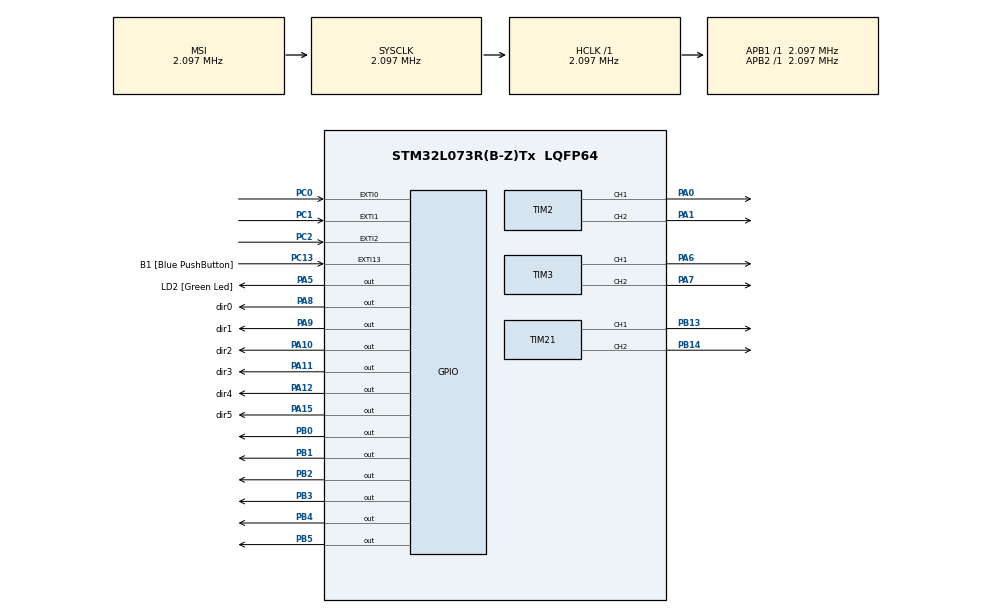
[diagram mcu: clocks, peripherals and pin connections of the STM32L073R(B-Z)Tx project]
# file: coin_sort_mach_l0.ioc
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FREERTOS.Tasks01=defaultTask,0,128,StartDefaultTask,Default
Mcu.Family=STM32L0
Mcu.Name=STM32L073R(B-Z)Tx
Mcu.Package=LQFP64
NVIC.EXTI0_1_IRQn=true\:3\:0\:false\:false\:true
NVIC.EXTI2_3_IRQn=true\:3\:0\:false\:false\:true
NVIC.EXTI4_15_IRQn=true\:3\:0\:false\:false\:true
NVIC.TIM21_IRQn=true\:3\:0\:false\:false\:true
NVIC.TIM2_IRQn=true\:3\:0\:false\:false\:true
NVIC.TIM3_IRQn=true\:3\:0\:false\:false\:true
PA0.Signal=S_TIM2_CH1
PA1.Signal=S_TIM2_CH2
PA10.GPIO_Label=dir2
PA10.Signal=GPIO_Output
PA11.GPIO_Label=dir3
PA11.Signal=GPIO_Output
PA12.GPIO_Label=dir4
PA12.Signal=GPIO_Output
PA13.GPIO_Label=TMS
PA13.Signal=SYS_SWDIO
PA14.GPIO_Label=TCK
PA14.Signal=SYS_SWCLK
PA15.GPIO_Label=dir5
PA15.Signal=GPIO_Output
PA2.GPIO_Label=USART_TX
PA2.Signal=USART2_TX
PA3.GPIO_Label=USART_RX
PA3.Signal=USART2_RX
PA5.GPIO_Label=LD2 [Green Led]
PA5.Signal=GPIO_Output
PA6.Signal=S_TIM3_CH1
PA7.Signal=S_TIM3_CH2
PA8.GPIO_Label=dir0
PA8.Signal=GPIO_Output
PA9.GPIO_Label=dir1
PA9.Signal=GPIO_Output
PB0.Signal=GPIO_Output
PB1.Signal=GPIO_Output
PB13.Signal=S_TIM21_CH1
PB14.Signal=S_TIM21_CH2
PB2.Signal=GPIO_Output
PB3.Signal=GPIO_Output
PB4.Signal=GPIO_Output
PB5.Signal=GPIO_Output
PC0.Signal=GPXTI0
PC1.Signal=GPXTI1
PC13.GPIO_Label=B1 [Blue PushButton]
PC13.Signal=GPXTI13
PC14-OSC32_IN.Signal=RCC_OSC32_IN
PC15-OSC32_OUT.Signal=RCC_OSC32_OUT
PC2.Signal=GPXTI2
PH0-OSC_IN.GPIO_Label=MCO
PH0-OSC_IN.Signal=RCC_OSC_IN
ProjectManager.HeapSize=0x200
ProjectManager.StackSize=0x400
ProjectManager.TargetToolchain=MDK-ARM V5
RCC.AHBFreq_Value=2097000
RCC.APB1Freq_Value=2097000
RCC.APB1TimFreq_Value=2097000
RCC.APB2Freq_Value=2097000
RCC.APB2TimFreq_Value=2097000
RCC.HSE_VALUE=8000000
RCC.HSI16_VALUE=16000000
RCC.HSI48_VALUE=48000000
RCC.HSI_VALUE=16000000
RCC.LSEState=RCC_LSE_ON
RCC.LSE_VALUE=32768
RCC.MSI_VALUE=2097000
RCC.SYSCLKFreq_VALUE=2097000
RCC.VCOOutputFreq_Value=48000000
SH.S_TIM21_CH1.0=TIM21_CH1,PWM Generation1 CH1
SH.S_TIM21_CH2.0=TIM21_CH2,PWM Generation2 CH2
SH.S_TIM2_CH1.0=TIM2_CH1,PWM Generation1 CH1
SH.S_TIM2_CH2.0=TIM2_CH2,PWM Generation2 CH2
SH.S_TIM3_CH1.0=TIM3_CH1,PWM Generation1 CH1
SH.S_TIM3_CH2.0=TIM3_CH2,PWM Generation2 CH2
TIM2.Channel-PWM\ Generation2\ CH2=TIM_CHANNEL_2
TIM21.Channel-PWM\ Generation2\ CH2=TIM_CHANNEL_2
TIM3.Channel-PWM\ Generation2\ CH2=TIM_CHANNEL_2
VP_FREERTOS_VS_ENABLE.Mode=Enabled
board=NUCLEO-L073RZ

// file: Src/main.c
/**
  ******************************************************************************
  * File Name          : main.c
  * Description        : Main program body
  ******************************************************************************
  *
  * COPYRIGHT(c) 2016 STMicroelectronics
  *
  * Redistribution and use in source and binary forms, with or without modification,
  * are permitted provided that the following conditions are met:
  *   1. Redistributions of source code must retain the above copyright notice,
  *      this list of conditions and the following disclaimer.
  *   2. Redistributions in binary form must reproduce the above copyright notice,
  *      this list of conditions and the following disclaimer in the documentation
  *      and/or other materials provided with the distribution.
  *   3. Neither the name of STMicroelectronics nor the names of its contributors
  *      may be used to endorse or promote products derived from this software
  *      without specific prior written permission.
  *
  * THIS SOFTWARE IS PROVIDED BY THE COPYRIGHT HOLDERS AND CONTRIBUTORS "AS IS"
  * AND ANY EXPRESS OR IMPLIED WARRANTIES, INCLUDING, BUT NOT LIMITED TO, THE
  * IMPLIED WARRANTIES OF MERCHANTABILITY AND FITNESS FOR A PARTICULAR PURPOSE ARE
  * DISCLAIMED. IN NO EVENT SHALL THE COPYRIGHT HOLDER OR CONTRIBUTORS BE LIABLE
  * FOR ANY DIRECT, INDIRECT, INCIDENTAL, SPECIAL, EXEMPLARY, OR CONSEQUENTIAL
  * DAMAGES (INCLUDING, BUT NOT LIMITED TO, PROCUREMENT OF SUBSTITUTE GOODS OR
  * SERVICES; LOSS OF USE, DATA, OR PROFITS; OR BUSINESS INTERRUPTION) HOWEVER
  * CAUSED AND ON ANY THEORY OF LIABILITY, WHETHER IN CONTRACT, STRICT LIABILITY,
  * OR TORT (INCLUDING NEGLIGENCE OR OTHERWISE) ARISING IN ANY WAY OUT OF THE USE
  * OF THIS SOFTWARE, EVEN IF ADVISED OF THE POSSIBILITY OF SUCH DAMAGE.
  *
  ******************************************************************************
  */
#include "stm32l0xx_hal.h"
#include "cmsis_os.h"
#include "tim.h"
#include "gpio.h"

/* USER CODE BEGIN PV */
/* Private variables ---------------------------------------------------------*/

/* USER CODE END PV */

void SystemClock_Config(void);
void MX_FREERTOS_Init(void);

/* USER CODE BEGIN PFP */
/* Private function prototypes -----------------------------------------------*/

/* USER CODE END PFP */

int main(void)
{

  /* MCU Configuration----------------------------------------------------------*/

  /* Reset of all peripherals, Initializes the Flash interface and the Systick. */
  HAL_Init();

  /* Configure the system clock */
  SystemClock_Config();

  /* Initialize all configured peripherals */
  MX_GPIO_Init();
  MX_TIM2_Init();
  MX_TIM3_Init();
  MX_TIM21_Init();

  /* USER CODE BEGIN 2 */
  HAL_GPIO_WritePin(GPIOA,dir1_Pin,GPIO_PIN_RESET);
  /* USER CODE END 2 */

  /* Call init function for freertos objects (in freertos.c) */
  MX_FREERTOS_Init();

  /* Start scheduler */
  osKernelStart();

  /* We should never get here as control is now taken by the scheduler */

  /* Infinite loop */
  while (1)
  {

  }

}

/** System Clock Configuration
*/
void SystemClock_Config(void)
{

  RCC_OscInitTypeDef RCC_OscInitStruct;
  RCC_ClkInitTypeDef RCC_ClkInitStruct;

  __HAL_RCC_PWR_CLK_ENABLE();

  __HAL_PWR_VOLTAGESCALING_CONFIG(PWR_REGULATOR_VOLTAGE_SCALE1);

  RCC_OscInitStruct.OscillatorType = RCC_OSCILLATORTYPE_MSI;
  RCC_OscInitStruct.MSIState = RCC_MSI_ON;
  RCC_OscInitStruct.MSICalibrationValue = 0;
  RCC_OscInitStruct.MSIClockRange = RCC_MSIRANGE_5;
  RCC_OscInitStruct.PLL.PLLState = RCC_PLL_NONE;
  HAL_RCC_OscConfig(&RCC_OscInitStruct);

  RCC_ClkInitStruct.ClockType = RCC_CLOCKTYPE_HCLK|RCC_CLOCKTYPE_SYSCLK
                              |RCC_CLOCKTYPE_PCLK1|RCC_CLOCKTYPE_PCLK2;
  RCC_ClkInitStruct.SYSCLKSource = RCC_SYSCLKSOURCE_MSI;
  RCC_ClkInitStruct.AHBCLKDivider = RCC_SYSCLK_DIV1;
  RCC_ClkInitStruct.APB1CLKDivider = RCC_HCLK_DIV1;
  RCC_ClkInitStruct.APB2CLKDivider = RCC_HCLK_DIV1;
  HAL_RCC_ClockConfig(&RCC_ClkInitStruct, FLASH_LATENCY_0);

  HAL_SYSTICK_Config(HAL_RCC_GetHCLKFreq()/1000);

  HAL_SYSTICK_CLKSourceConfig(SYSTICK_CLKSOURCE_HCLK);

  /* SysTick_IRQn interrupt configuration */
  HAL_NVIC_SetPriority(SysTick_IRQn, 3, 0);
}

/************************ (C) COPYRIGHT STMicroelectronics *****END OF FILE****/

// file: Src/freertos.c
/**
  ******************************************************************************
  * File Name          : freertos.c
  * Description        : Code for freertos applications
  ******************************************************************************
  *
  * COPYRIGHT(c) 2016 STMicroelectronics
  *
  * Redistribution and use in source and binary forms, with or without modification,
  * are permitted provided that the following conditions are met:
  *   1. Redistributions of source code must retain the above copyright notice,
  *      this list of conditions and the following disclaimer.
  *   2. Redistributions in binary form must reproduce the above copyright notice,
  *      this list of conditions and the following disclaimer in the documentation
  *      and/or other materials provided with the distribution.
  *   3. Neither the name of STMicroelectronics nor the names of its contributors
  *      may be used to endorse or promote products derived from this software
  *      without specific prior written permission.
  *
  * THIS SOFTWARE IS PROVIDED BY THE COPYRIGHT HOLDERS AND CONTRIBUTORS "AS IS"
  * AND ANY EXPRESS OR IMPLIED WARRANTIES, INCLUDING, BUT NOT LIMITED TO, THE
  * IMPLIED WARRANTIES OF MERCHANTABILITY AND FITNESS FOR A PARTICULAR PURPOSE ARE
  * DISCLAIMED. IN NO EVENT SHALL THE COPYRIGHT HOLDER OR CONTRIBUTORS BE LIABLE
  * FOR ANY DIRECT, INDIRECT, INCIDENTAL, SPECIAL, EXEMPLARY, OR CONSEQUENTIAL
  * DAMAGES (INCLUDING, BUT NOT LIMITED TO, PROCUREMENT OF SUBSTITUTE GOODS OR
  * SERVICES; LOSS OF USE, DATA, OR PROFITS; OR BUSINESS INTERRUPTION) HOWEVER
  * CAUSED AND ON ANY THEORY OF LIABILITY, WHETHER IN CONTRACT, STRICT LIABILITY,
  * OR TORT (INCLUDING NEGLIGENCE OR OTHERWISE) ARISING IN ANY WAY OUT OF THE USE
  * OF THIS SOFTWARE, EVEN IF ADVISED OF THE POSSIBILITY OF SUCH DAMAGE.
  *
  ******************************************************************************
  */

#include "FreeRTOS.h"
#include "task.h"
#include "cmsis_os.h"

#include "config.h"
#include "thread_push.h"

//osThreadId defaultTaskHandle;

//void StartDefaultTask(void const * argument);

void MX_FREERTOS_Init(void); /* (MISRA C 2004 rule 8.1) */

/* Hook prototypes */

/* Init FreeRTOS */

void MX_FREERTOS_Init(void) {

  /* Create the thread(s) */
  /* definition and creation of defaultTask */
	/*
  osThreadDef(defaultTask, StartDefaultTask, osPriorityNormal, 0, 128);
  defaultTaskHandle = osThreadCreate(osThread(defaultTask), NULL);
  */

  /* USER CODE BEGIN RTOS_THREADS */
  /* add threads, ... */
	osThreadDef(thread_push,thread_push_entry,osPriorityRealtime,1,128);
	thread_push_id    = osThreadCreate(osThread(thread_push),NULL);
  /* USER CODE END RTOS_THREADS */

  /* USER CODE BEGIN RTOS_QUEUES */
  /* add queues, ... */
	osMessageQDef(mesq,MesQ_Size,uint32_t);
	mesq_id           = osMessageCreate(osMessageQ(mesq),thread_push_id);
  /* USER CODE END RTOS_QUEUES */
}

/* StartDefaultTask function */
//void StartDefaultTask(void const * argument)
//{

  /* USER CODE BEGIN StartDefaultTask */
  /* Infinite loop */
//  {
		//HAL_GPIO_TogglePin(LD2_GPIO_Port,LD2_Pin);
//    osDelay(1);
//  }
  /* USER CODE END StartDefaultTask */
//}

/************************ (C) COPYRIGHT STMicroelectronics *****END OF FILE****/
